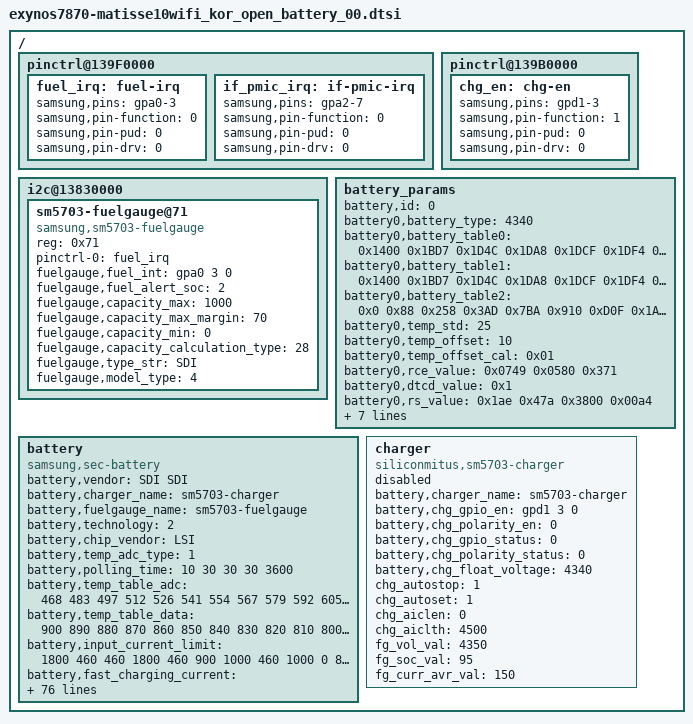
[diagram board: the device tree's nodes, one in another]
/*
 * SAMSUNG UNIVERSAL5433 board device tree source
 *
 * Copyright (c) 2015 Samsung Electronics Co., Ltd.
 *		http://www.samsung.com
 *
 * This program is free software; you can redistribute it and/or modify
 * it under the terms of the GNU General Public License version 2 as
 * published by the Free Software Foundation.
*/

/ {
	pinctrl@139F0000 {
		fuel_irq: fuel-irq {
			samsung,pins = "gpa0-3";
			samsung,pin-function = <0>;
			samsung,pin-pud = <0>;
			samsung,pin-drv = <0>;
		};
	};

	pinctrl@139F0000 {
		if_pmic_irq: if-pmic-irq {
			samsung,pins = "gpa2-7";
			samsung,pin-function = <0>;
			samsung,pin-pud = <0>;
			samsung,pin-drv = <0>;
		};
	};

	pinctrl@139B0000 {
		chg_en: chg-en {
			samsung,pins = "gpd1-3";
			samsung,pin-function = <1>;
			samsung,pin-pud = <0>;
			samsung,pin-drv = <0>;
		};
	};

	i2c@13830000 {
		status = "okay";
		sm5703-fuelgauge@71 {
			compatible = "samsung,sm5703-fuelgauge";
			reg = <0x71>;
			pinctrl-names = "default";
			pinctrl-0 = <&fuel_irq>;
			fuelgauge,fuel_int = <&gpa0 3 0>;
			fuelgauge,fuel_alert_soc = <2>;
			fuelgauge,capacity_max = <1000>;
			fuelgauge,capacity_max_margin = <70>;
			fuelgauge,capacity_min = <0>;
			fuelgauge,capacity_calculation_type = <28>;
			fuelgauge,type_str = "SDI";
			fuelgauge,model_type = <4>;
		};
	};
	battery_params {
		battery,id = <0>; /* -1 means auto, detected by F/G */
		battery0,battery_type = <4340>; /* 4200 4350 4400 */
		battery0,battery_table0 = <0x1400 0x1BD7 0x1D4C 0x1DA8 0x1DCF 0x1DF4 0x1E48 0x1EE3 0x1F45 0x1FCA 0x1FFA 0x207B 0x20C4 0x2192 0x2276 0x2399>;
		battery0,battery_table1 = <0x1400 0x1BD7 0x1D4C 0x1DA8 0x1DCF 0x1DF4 0x1E48 0x1EE3 0x1F45 0x1FCA 0x1FFA 0x207B 0x20C4 0x2192 0x2276 0x2399>;
		battery0,battery_table2 = <0x0 0x88 0x258 0x3AD 0x7BA 0x910 0xD0F 0x1A7E 0x1E7E 0x228B 0x2536 0x27E0 0x2A98 0x2FED 0x354F 0x3578>;
		battery0,temp_std = <25>;
		battery0,temp_offset = <10>;
		battery0,temp_offset_cal = <0x01>;
		battery0,rce_value = <0x0749 0x0580 0x371>;
		battery0,dtcd_value = <0x1>;
		battery0,rs_value = <0x1ae 0x47a 0x3800 0x00a4>; /*rs mix_factor max min*/
		battery0,vit_period = <0x350a>;
		battery0,mix_value = <0x0403 0x0004>; /*mix_rate init_blank*/
		battery0,topoff_soc = <0x0 0x5>; /*enable soc*/
		battery0,tem_poff = <3380 100 3300 100>;
		battery0,charge_offset_cal = <(-0x02)>;
		battery0,volt_cal = <0x809E>;
		battery0,curr_cal = <0x7B85>;
	};

	battery {
		status = "okay";

		pinctrl-names = "default";

		compatible = "samsung,sec-battery";
		battery,vendor = "SDI SDI";
		battery,charger_name = "sm5703-charger";
		battery,fuelgauge_name = "sm5703-fuelgauge";
		battery,technology = <2>; /* POWER_SUPPLY_TECHNOLOGY_LION */
		/* .temp_cohot = -1000; */
		/* .temp_cocold = -4325; */

		battery,chip_vendor = "LSI";
		battery,temp_adc_type = <1>; /* SEC_BATTERY_ADC_TYPE_AP */

		battery,polling_time = <10 30 30 30 3600>;



		battery,temp_table_adc = <468 483 497 512 526 541 554 567 579 592 605
					619 633 647 661 675 694 713 732 751 771
					787 804 821 837 854 874 894 914 934 954
					980 1006 1032 1058 1084 1109 1133 1158 1183
					1208 1236 1264 1292 1320 1348 1372 1397 1422
					1446 1471 1513 1554 1596 1637 1679 1722 1766
					1809 1853 1897 1931 1965 2000 2034 2069 2091
					2113 2136 2158 2181 2233 2286 2338 2391 2443
					2469 2495 2522 2548 2574 2621 2668 2715 2762
					2810 2846 2882 2918 2955 2991 3023 3055 3087
					3119 3152 3183 3214 3245 3276 3307 3335 3364
					3392 3421 3449 3472 3495 3518 3541 3564>;

		battery,temp_table_data = <900 890 880 870 860 850 840 830 820 810 800
					790 780 770 760 750 740 730 720 710 700
					690 680 670 660 650 640 630 620 610 600
					590 580 570 560 550 540 530 520 510 500
					490 480 470 460 450 440 430 420 410 400
					390 380 370 360 350 340 330 320 310 300
					290 280 270 260 250 240 230 220 210 200
					190 180 170 160 150 140 130 120 110 100
					90 80 70 60 50 40 30 20 10 0
					(-10) (-20) (-30) (-40) (-50) (-60) (-70) (-80) (-90) (-100)
					 (-110) (-120) (-130) (-140) (-150) (-160) (-170) (-180) (-190) (-200)>;

		battery,input_current_limit = <1800 460 460 1800 460 900 1000 460 1000 0 820 820 820 1450 1800 0 1000 400 700 1300 300 1000 1800 0 1450 1450 1000 1800 80 1800 1800 1400 1000 1000 820 820>;
		battery,fast_charging_current = <2100 0 0 2100 460 1200 1000 460 1200 0 1200 1200 1200 1600 2100 0 1200 400 700 1300 300 1000 1900 0 2100 2100 1000 2100 80 1800 1000 1400 0 1000 1200 1200>;
		battery,full_check_current_1st = <300 0 0 300 300 300 300 300 300 0 300 300 300 300 300 0 300 300 300 300 300 300 300 0 300 300 300 300 0 300 300 300 0 300 300 300>;
		battery,full_check_current_2nd = <225 0 0 225 225 225 225 225 225 0 225 225 225 225 225 0 225 225 225 225 225 225 225 0 225 225 225 225 0 225 225 225 0 225 225 225>;

		battery,inbat_voltage = <1>;
		battery,inbat_voltage_table_adc = <2780 2758 2727 2701 2678 2650 2621 2596 2564 2532 2503 2478 2445 2424 2394 2362 2336 2309 2279 2252>;
		battery,inbat_voltage_table_data = <434 430 425 420 415 410 405 400 395 390 385 380 375 370 365 360 355 350 345 340>;


		battery,adc_check_count = <5>;

		battery,cable_check_type = <4>; /* SEC_BATTERY_CABLE_CHECK_PSY */
		battery,cable_source_type = <1>; /* SEC_BATTERY_CABLE_SOURCE_EXTERNAL */
		battery,polling_type = <1>; /* SEC_BATTERY_MONITOR_ALARM */
		battery,monitor_initial_count = <0>;

		battery,battery_check_type = <0>; /* SEC_BATTERY_CHECK_NONE */
		battery,check_count = <0>;

		battery,check_adc_max = <1440>;
		battery,check_adc_min = <0>;

		battery,ovp_uvlo_check_type = <3>; /* SEC_BATTERY_OVP_UVLO_CHGPOLLING */

		battery,thermal_source = <2>; /* SEC_BATTERY_THERMAL_SOURCE_ADC */

		battery,temp_check_type = <2>; /* SEC_BATTERY_TEMP_CHECK_TEMP */
		battery,temp_check_count = <1>;
		battery,temp_highlimit_threshold_normal = <800>;
		battery,temp_highlimit_recovery_normal = <750>;
		battery,temp_high_threshold_normal = <550>;
		battery,temp_high_recovery_normal = <500>;
		battery,temp_low_threshold_normal = <(-50)>;
		battery,temp_low_recovery_normal = <0>;
		battery,temp_highlimit_threshold_lpm = <800>;
		battery,temp_highlimit_recovery_lpm = <750>;
		battery,temp_high_threshold_lpm = <550>;
		battery,temp_high_recovery_lpm = <500>;
		battery,temp_low_threshold_lpm = <(-50)>;
		battery,temp_low_recovery_lpm = <0>;
		battery,full_check_type = <7>; /* SEC_BATTERY_FULLCHARGED_CHGPSY */
		battery,full_check_type_2nd = <7>; /* SEC_BATTERY_FULLCHARGED_CHGPSY */
		battery,full_check_count = <1>;
		battery,chg_gpio_full_check = <0>;
		battery,chg_polarity_full_check = <1>;

		/* SEC_BATTERY_FULL_CONDITION_SOC |
		   SEC_BATTERY_FULL_CONDITION_NOTIMEFULL |
		   SEC_BATTERY_FULL_CONDITION_VCELL */
		battery,full_condition_type = <13>;
		battery,full_condition_soc = <93>;
		battery,full_condition_vcell = <4240>;

		battery,recharge_check_count = <2>;
		battery,recharge_condition_type = <4>; /* SEC_BATTERY_RECHARGE_CONDITION_VCELL */
		battery,recharge_condition_soc = <98>;
		battery,recharge_condition_vcell = <4300>;

		battery,charging_total_time = <36000>;
		battery,recharging_total_time = <5400>;
		battery,charging_reset_time = <0>;

		battery,always_enable;

		io-channels = <&exynos_adc 1>, <&exynos_adc 3>;
		io-channel-names = "adc-temp", "adc-in-bat";
		#io-channel-cells = <1>;
		io-channel-ranges;

		battery,chg_float_voltage = <4340>;

		battery,self_discharging_en;
		battery,force_discharging_limit = <650>;
		battery,force_discharging_recov = <550>;
		battery,self_discharging_voltage_limit = <4250>;
		battery,discharging_adc_max = <2600>;
		battery,discharging_adc_min = <1700>;
		battery,discharging_ntc_limit = <2750>;

		battery,self_discharging_temp_block = <600>;
		battery,self_discharging_volt_block = <4250>;
		battery,self_discharging_temp_recov = <550>;
		battery,self_discharging_temp_pollingtime = <400>;

		battery,swelling_high_temp_block = <450>;
		battery,swelling_high_temp_recov = <400>;
		battery,swelling_low_temp_block = <100>;
		battery,swelling_low_temp_recov = <150>;
		battery,swelling_low_temp_current = <1800>;	/* 0.5C */
		battery,swelling_low_temp_topoff = <150>;	/* 0.05C */
		battery,swelling_high_temp_current = <1800>;	/* 0.7C */
		battery,swelling_high_temp_topoff = <150>;	/* 0.05C */
		battery,swelling_drop_float_voltage = <4200>;
		battery,swelling_high_rechg_voltage = <4150>;
		battery,swelling_low_rechg_voltage = <4050>;
	};

	charger {
		status = "disable";
		compatible = "siliconmitus,sm5703-charger";

		/* Charger */
		battery,charger_name = "sm5703-charger";
		battery,chg_gpio_en = <&gpd1 3 0>;
		battery,chg_polarity_en = <0>;
		battery,chg_gpio_status = <0>;
		battery,chg_polarity_status = <0>;
		battery,chg_float_voltage = <4340>;
		chg_autostop = <1>;
		chg_autoset = <1>;
		chg_aiclen = <0>;
		chg_aiclth = <4500>;
		fg_vol_val = <4350>;
		fg_soc_val = <95>;
		fg_curr_avr_val = <150>;
	};
};
